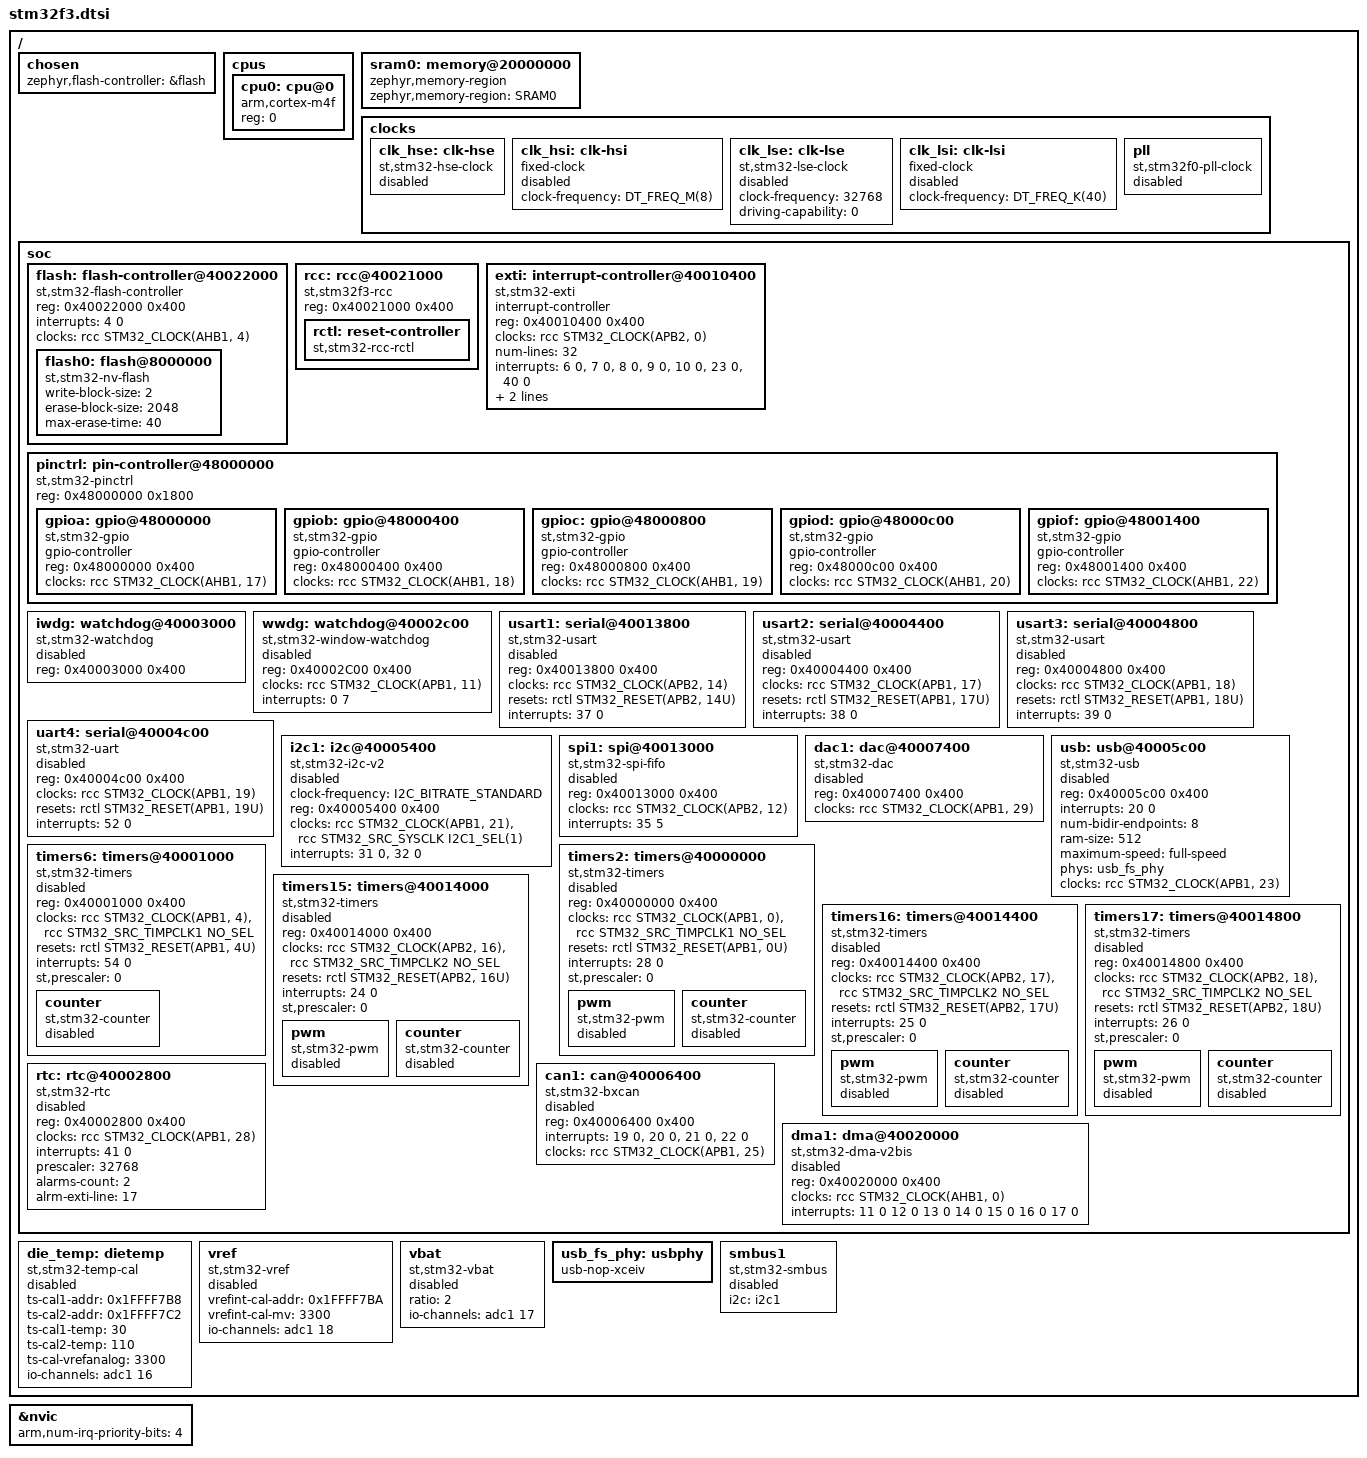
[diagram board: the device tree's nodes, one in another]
/*
 * Copyright (c) 2017 I-SENSE group of ICCS
 * Copyright (c) 2019 Centaur Analytics, Inc
 * Copyright (c) 2024 STMicroelectronics
 *
 * SPDX-License-Identifier: Apache-2.0
 */

#include <arm/armv7-m.dtsi>
#include <zephyr/dt-bindings/clock/stm32f3_clock.h>
#include <zephyr/dt-bindings/i2c/i2c.h>
#include <zephyr/dt-bindings/gpio/gpio.h>
#include <zephyr/dt-bindings/pwm/pwm.h>
#include <zephyr/dt-bindings/pwm/stm32_pwm.h>
#include <zephyr/dt-bindings/dma/stm32_dma.h>
#include <zephyr/dt-bindings/reset/stm32f0_1_3_reset.h>
#include <zephyr/dt-bindings/adc/adc.h>
#include <freq.h>

/ {
	chosen {
		zephyr,flash-controller = &flash;
	};

	cpus {
		#address-cells = <1>;
		#size-cells = <0>;

		cpu0: cpu@0 {
			device_type = "cpu";
			compatible = "arm,cortex-m4f";
			reg = <0>;
		};
	};

	sram0: memory@20000000 {
		compatible = "zephyr,memory-region", "mmio-sram";
		zephyr,memory-region = "SRAM0";
	};

	clocks {
		clk_hse: clk-hse {
			#clock-cells = <0>;
			compatible = "st,stm32-hse-clock";
			status = "disabled";
		};

		clk_hsi: clk-hsi {
			#clock-cells = <0>;
			compatible = "fixed-clock";
			clock-frequency = <DT_FREQ_M(8)>;
			status = "disabled";
		};

		clk_lse: clk-lse {
			#clock-cells = <0>;
			compatible = "st,stm32-lse-clock";
			clock-frequency = <32768>;
			driving-capability = <0>;
			status = "disabled";
		};

		clk_lsi: clk-lsi {
			#clock-cells = <0>;
			compatible = "fixed-clock";
			clock-frequency = <DT_FREQ_K(40)>;
			status = "disabled";
		};

		pll: pll {
			#clock-cells = <0>;
			compatible = "st,stm32f0-pll-clock";
			status = "disabled";
		};
	};

	soc {
		flash: flash-controller@40022000 {
			compatible = "st,stm32-flash-controller", "st,stm32f1-flash-controller";
			reg = <0x40022000 0x400>;
			interrupts = <4 0>;
			clocks = <&rcc STM32_CLOCK(AHB1, 4)>;

			#address-cells = <1>;
			#size-cells = <1>;

			flash0: flash@8000000 {
				compatible = "st,stm32-nv-flash", "soc-nv-flash";

				write-block-size = <2>;
				erase-block-size = <2048>;
				/* maximum erase time for a 2K sector */
				max-erase-time = <40>;
			};
		};

		rcc: rcc@40021000 {
			compatible = "st,stm32f3-rcc";
			#clock-cells = <2>;
			reg = <0x40021000 0x400>;

			rctl: reset-controller {
				compatible = "st,stm32-rcc-rctl";
				#reset-cells = <1>;
			};
		};

		exti: interrupt-controller@40010400 {
			compatible = "st,stm32-exti";
			interrupt-controller;
			#interrupt-cells = <1>;
			#address-cells = <1>;
			reg = <0x40010400 0x400>;
			clocks = <&rcc STM32_CLOCK(APB2, 0)>;
			num-lines = <32>;
			interrupts = <6 0>, <7 0>, <8 0>, <9 0>,
				     <10 0>, <23 0>, <40 0>;
			interrupt-names = "line0", "line1", "line2", "line3",
					  "line4", "line5-9", "line10-15";
			line-ranges = <0 1>, <1 1>, <2 1>, <3 1>,
				      <4 1>, <5 5>, <10 6>;
		};

		pinctrl: pin-controller@48000000 {
			compatible = "st,stm32-pinctrl";
			#address-cells = <1>;
			#size-cells = <1>;
			reg = <0x48000000 0x1800>;

			gpioa: gpio@48000000 {
				compatible = "st,stm32-gpio";
				gpio-controller;
				#gpio-cells = <2>;
				reg = <0x48000000 0x400>;
				clocks = <&rcc STM32_CLOCK(AHB1, 17)>;
			};

			gpiob: gpio@48000400 {
				compatible = "st,stm32-gpio";
				gpio-controller;
				#gpio-cells = <2>;
				reg = <0x48000400 0x400>;
				clocks = <&rcc STM32_CLOCK(AHB1, 18)>;
			};

			gpioc: gpio@48000800 {
				compatible = "st,stm32-gpio";
				gpio-controller;
				#gpio-cells = <2>;
				reg = <0x48000800 0x400>;
				clocks = <&rcc STM32_CLOCK(AHB1, 19)>;
			};

			gpiod: gpio@48000c00 {
				compatible = "st,stm32-gpio";
				gpio-controller;
				#gpio-cells = <2>;
				reg = <0x48000c00 0x400>;
				clocks = <&rcc STM32_CLOCK(AHB1, 20)>;
			};

			gpiof: gpio@48001400 {
				compatible = "st,stm32-gpio";
				gpio-controller;
				#gpio-cells = <2>;
				reg = <0x48001400 0x400>;
				clocks = <&rcc STM32_CLOCK(AHB1, 22)>;
			};
		};

		iwdg: watchdog@40003000 {
			compatible = "st,stm32-watchdog";
			reg = <0x40003000 0x400>;
			status = "disabled";
		};

		wwdg: watchdog@40002c00 {
			compatible = "st,stm32-window-watchdog";
			reg = <0x40002C00 0x400>;
			clocks = <&rcc STM32_CLOCK(APB1, 11)>;
			interrupts = <0 7>;
			status = "disabled";
		};

		usart1: serial@40013800 {
			compatible = "st,stm32-usart", "st,stm32-uart";
			reg = <0x40013800 0x400>;
			clocks = <&rcc STM32_CLOCK(APB2, 14)>;
			resets = <&rctl STM32_RESET(APB2, 14U)>;
			interrupts = <37 0>;
			status = "disabled";
		};

		usart2: serial@40004400 {
			compatible = "st,stm32-usart", "st,stm32-uart";
			reg = <0x40004400 0x400>;
			clocks = <&rcc STM32_CLOCK(APB1, 17)>;
			resets = <&rctl STM32_RESET(APB1, 17U)>;
			interrupts = <38 0>;
			status = "disabled";
		};

		usart3: serial@40004800 {
			compatible = "st,stm32-usart", "st,stm32-uart";
			reg = <0x40004800 0x400>;
			clocks = <&rcc STM32_CLOCK(APB1, 18)>;
			resets = <&rctl STM32_RESET(APB1, 18U)>;
			interrupts = <39 0>;
			status = "disabled";
		};

		uart4: serial@40004c00 {
			compatible = "st,stm32-uart";
			reg = <0x40004c00 0x400>;
			clocks = <&rcc STM32_CLOCK(APB1, 19)>;
			resets = <&rctl STM32_RESET(APB1, 19U)>;
			interrupts = <52 0>;
			status = "disabled";
		};

		i2c1: i2c@40005400 {
			compatible = "st,stm32-i2c-v2";
			clock-frequency = <I2C_BITRATE_STANDARD>;
			#address-cells = <1>;
			#size-cells = <0>;
			reg = <0x40005400 0x400>;
			clocks = <&rcc STM32_CLOCK(APB1, 21)>,
				 /* I2C clock source should always be defined,
				  * even for the default value
				  */
				 <&rcc STM32_SRC_SYSCLK I2C1_SEL(1)>;
			interrupts = <31 0>, <32 0>;
			interrupt-names = "event", "error";
			status = "disabled";
		};

		spi1: spi@40013000 {
			compatible = "st,stm32-spi-fifo", "st,stm32-spi";
			#address-cells = <1>;
			#size-cells = <0>;
			reg = <0x40013000 0x400>;
			clocks = <&rcc STM32_CLOCK(APB2, 12)>;
			interrupts = <35 5>;
			status = "disabled";
		};

		dac1: dac@40007400 {
			compatible = "st,stm32-dac";
			reg = <0x40007400 0x400>;
			clocks = <&rcc STM32_CLOCK(APB1, 29)>;
			status = "disabled";
			#io-channel-cells = <1>;
		};

		usb: usb@40005c00 {
			compatible = "st,stm32-usb";
			reg = <0x40005c00 0x400>;
			interrupts = <20 0>;
			interrupt-names = "usb";
			num-bidir-endpoints = <8>;
			ram-size = <512>;
			maximum-speed = "full-speed";
			phys = <&usb_fs_phy>;
			clocks = <&rcc STM32_CLOCK(APB1, 23)>;
			status = "disabled";
		};

		timers2: timers@40000000 {
			compatible = "st,stm32-timers";
			reg = <0x40000000 0x400>;
			clocks = <&rcc STM32_CLOCK(APB1, 0)>,
				 <&rcc STM32_SRC_TIMPCLK1 NO_SEL>;
			resets = <&rctl STM32_RESET(APB1, 0U)>;
			interrupts = <28 0>;
			interrupt-names = "global";
			st,prescaler = <0>;
			status = "disabled";

			pwm {
				compatible = "st,stm32-pwm";
				status = "disabled";
				#pwm-cells = <3>;
			};

			counter {
				compatible = "st,stm32-counter";
				status = "disabled";
			};
		};

		timers6: timers@40001000 {
			compatible = "st,stm32-timers";
			reg = <0x40001000 0x400>;
			clocks = <&rcc STM32_CLOCK(APB1, 4)>,
				 <&rcc STM32_SRC_TIMPCLK1 NO_SEL>;
			resets = <&rctl STM32_RESET(APB1, 4U)>;
			interrupts = <54 0>;
			interrupt-names = "global";
			st,prescaler = <0>;
			status = "disabled";

			counter {
				compatible = "st,stm32-counter";
				status = "disabled";
			};
		};

		timers15: timers@40014000 {
			compatible = "st,stm32-timers";
			reg = <0x40014000 0x400>;
			clocks = <&rcc STM32_CLOCK(APB2, 16)>,
				 <&rcc STM32_SRC_TIMPCLK2 NO_SEL>;
			resets = <&rctl STM32_RESET(APB2, 16U)>;
			interrupts = <24 0>;
			interrupt-names = "global";
			st,prescaler = <0>;
			status = "disabled";

			pwm {
				compatible = "st,stm32-pwm";
				status = "disabled";
				#pwm-cells = <3>;
			};

			counter {
				compatible = "st,stm32-counter";
				status = "disabled";
			};
		};

		timers16: timers@40014400 {
			compatible = "st,stm32-timers";
			reg = <0x40014400 0x400>;
			clocks = <&rcc STM32_CLOCK(APB2, 17)>,
				 <&rcc STM32_SRC_TIMPCLK2 NO_SEL>;
			resets = <&rctl STM32_RESET(APB2, 17U)>;
			interrupts = <25 0>;
			interrupt-names = "global";
			st,prescaler = <0>;
			status = "disabled";

			pwm {
				compatible = "st,stm32-pwm";
				status = "disabled";
				#pwm-cells = <3>;
			};

			counter {
				compatible = "st,stm32-counter";
				status = "disabled";
			};
		};

		timers17: timers@40014800 {
			compatible = "st,stm32-timers";
			reg = <0x40014800 0x400>;
			clocks = <&rcc STM32_CLOCK(APB2, 18)>,
				 <&rcc STM32_SRC_TIMPCLK2 NO_SEL>;
			resets = <&rctl STM32_RESET(APB2, 18U)>;
			interrupts = <26 0>;
			interrupt-names = "global";
			st,prescaler = <0>;
			status = "disabled";

			pwm {
				compatible = "st,stm32-pwm";
				status = "disabled";
				#pwm-cells = <3>;
			};

			counter {
				compatible = "st,stm32-counter";
				status = "disabled";
			};
		};

		rtc: rtc@40002800 {
			compatible = "st,stm32-rtc";
			reg = <0x40002800 0x400>;
			clocks = <&rcc STM32_CLOCK(APB1, 28)>;
			interrupts = <41 0>;
			prescaler = <32768>;
			alarms-count = <2>;
			alrm-exti-line = <17>;
			status = "disabled";
		};

		can1: can@40006400 {
			compatible = "st,stm32-bxcan";
			reg = <0x40006400 0x400>;
			interrupts = <19 0>, <20 0>, <21 0>, <22 0>;
			interrupt-names = "TX", "RX0", "RX1", "SCE";
			clocks = <&rcc STM32_CLOCK(APB1, 25)>;
			status = "disabled";
		};

		dma1: dma@40020000 {
			compatible = "st,stm32-dma-v2bis";
			#dma-cells = <2>;
			reg = <0x40020000 0x400>;
			clocks = <&rcc STM32_CLOCK(AHB1, 0)>;
			interrupts = <11 0 12 0 13 0 14 0 15 0 16 0 17 0>;
			status = "disabled";
		};
	};

	die_temp: dietemp {
		compatible = "st,stm32-temp-cal";
		ts-cal1-addr = <0x1FFFF7B8>;
		ts-cal2-addr = <0x1FFFF7C2>;
		ts-cal1-temp = <30>;
		ts-cal2-temp = <110>;
		ts-cal-vrefanalog = <3300>;
		io-channels = <&adc1 16>;
		status = "disabled";
	};

	vref: vref {
		compatible = "st,stm32-vref";
		vrefint-cal-addr = <0x1FFFF7BA>;
		vrefint-cal-mv = <3300>;
		io-channels = <&adc1 18>;
		status = "disabled";
	};

	vbat: vbat {
		compatible = "st,stm32-vbat";
		ratio = <2>;
		io-channels = <&adc1 17>;
		status = "disabled";
	};

	usb_fs_phy: usbphy {
		compatible = "usb-nop-xceiv";
		#phy-cells = <0>;
	};

	smbus1: smbus1 {
		compatible = "st,stm32-smbus";
		#address-cells = <1>;
		#size-cells = <0>;
		i2c = <&i2c1>;
		status = "disabled";
	};
};

&nvic {
	arm,num-irq-priority-bits = <4>;
};
